# TMS320F280049 register map
Vendor: Texas Instruments; Series: C2000 F28004x; File version: 0.2.0-generated
Registers are 16-bit, read-write, reset 0x0 unless marked. A register's access mark holds for its fields unless they carry their own. Offsets are from the block's base; [hi:lo] are bit positions.

## ACCESSPROTECTIONREGS — ACCESS PROTECTION Registers
Base 0x000BE980
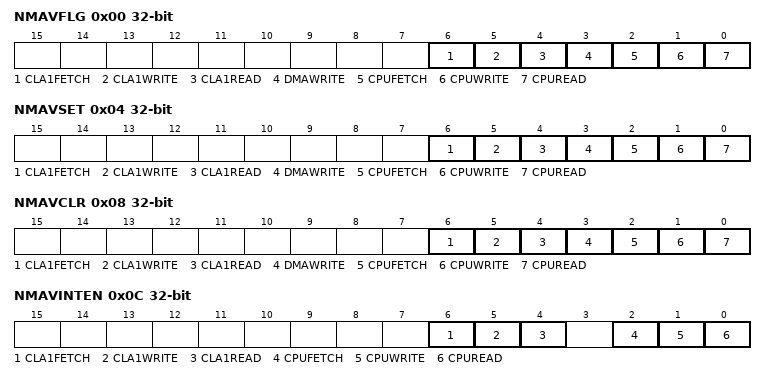
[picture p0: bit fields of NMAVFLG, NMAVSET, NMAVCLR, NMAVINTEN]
0x00 NMAVFLG 32-bit — Non-Master Access Violation Flag Register
  [6] CLA1FETCH — Non Master CLA1 Fetch Access Violation Flag
  [5] CLA1WRITE — Non Master CLA1 Write Access Violation Flag
  [4] CLA1READ — Non Master CLA1 Read Access Violation Flag
  [3] DMAWRITE — Non Master DMA Write Access Violation Flag
  [2] CPUFETCH — Non Master CPU Fetch Access Violation Flag
  [1] CPUWRITE — Non Master CPU Write Access Violation Flag
  [0] CPUREAD — Non Master CPU Read Access Violation Flag
0x04 NMAVSET 32-bit — Non-Master Access Violation Flag Set Register
  [6] CLA1FETCH — Non Master CLA1 Fetch Access Violation Flag Set
  [5] CLA1WRITE — Non Master CLA1 Write Access Violation Flag Set
  [4] CLA1READ — Non Master CLA1 Read Access Violation Flag Set
  [3] DMAWRITE — Non Master DMA Write Access Violation Flag Set
  [2] CPUFETCH — Non Master CPU Fetch Access Violation Flag Set
  [1] CPUWRITE — Non Master CPU Write Access Violation Flag Set
  [0] CPUREAD — Non Master CPU Read Access Violation Flag Set
0x08 NMAVCLR 32-bit — Non-Master Access Violation Flag Clear Register
  [6] CLA1FETCH — Non Master CLA1 Fetch Access Violation Flag Clear
  [5] CLA1WRITE — Non Master CLA1 Write Access Violation Flag Clear
  [4] CLA1READ — Non Master CLA1 Read Access Violation Flag Clear
  [3] DMAWRITE — Non Master DMA Write Access Violation Flag Clear
  [2] CPUFETCH — Non Master CPU Fetch Access Violation Flag Clear
  [1] CPUWRITE — Non Master CPU Write Access Violation Flag Clear
  [0] CPUREAD — Non Master CPU Read Access Violation Flag Clear
0x0C NMAVINTEN 32-bit — Non-Master Access Violation Interrupt Enable Register
  [6] CLA1FETCH — Non Master CLA1 Fetch Access Violation Interrupt Enable
  [5] CLA1WRITE — Non Master CLA1 Write Access Violation Interrupt Enable
  [4] CLA1READ — Non Master CLA1 Read Access Violation Interrupt Enable
  [2] CPUFETCH — Non Master CPU Fetch Access Violation Interrupt Enable
  [1] CPUWRITE — Non Master CPU Write Access Violation Interrupt Enable
  [0] CPUREAD — Non Master CPU Read Access Violation Interrupt Enable
0x10 NMCPURDAVADDR 32-bit — Non-Master CPU Read Access Violation Address
  [31] NMCPURDAVADDR — Non Master CPU read access violation address register.
0x14 NMCPUWRAVADDR 32-bit — Non-Master CPU Write Access Violation Address
  [31] NMCPUWRAVADDR — Non Master CPU write access violation address register.
0x18 NMCPUFAVADDR 32-bit — Non-Master CPU Fetch Access Violation Address
  [31] NMCPUFAVADDR — Non Master CPU fetch access violation address register.
0x1C NMDMAWRAVADDR 32-bit — Non-Master DMA Write Access Violation Address
0x20 NMCLA1RDAVADDR 32-bit — Non-Master CLA1 Read Access Violation Address
  [31] NMCLA1RDAVADDR — Non Master CLA1 read access violation address register.
0x24 NMCLA1WRAVADDR 32-bit — Non-Master CLA1 Write Access Violation Address
  [31] NMCLA1WRAVADDR — Non Master CLA1 write access violation address register.
0x28 NMCLA1FAVADDR 32-bit — Non-Master CLA1 Fetch Access Violation Address
  [31] NMCLA1FAVADDR — Non Master CLA1 fetch access violation address register.
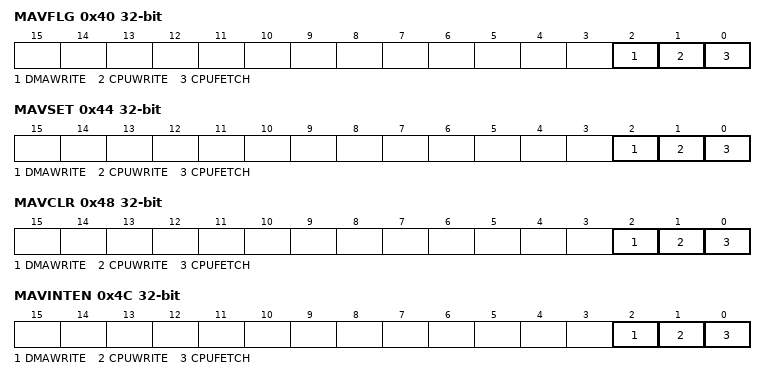
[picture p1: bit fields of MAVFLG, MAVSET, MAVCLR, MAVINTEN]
0x40 MAVFLG 32-bit — Master Access Violation Flag Register
  [2] DMAWRITE — Master DMA Write Access Violation Flag
  [1] CPUWRITE — Master CPU Write Access Violation Flag
  [0] CPUFETCH — Master CPU Fetch Access Violation Flag
0x44 MAVSET 32-bit — Master Access Violation Flag Set Register
  [2] DMAWRITE — Master DMA Write Access Violation Flag Set
  [1] CPUWRITE — Master CPU Write Access Violation Flag Set
  [0] CPUFETCH — Master CPU Fetch Access Violation Flag Set
0x48 MAVCLR 32-bit — Master Access Violation Flag Clear Register
  [2] DMAWRITE — Master DMA Write Access Violation Flag Clear
  [1] CPUWRITE — Master CPU Write Access Violation Flag Clear
  [0] CPUFETCH — Master CPU Fetch Access Violation Flag Clear
0x4C MAVINTEN 32-bit — Master Access Violation Interrupt Enable Register
  [2] DMAWRITE — Master DMA Write Access Violation Interrupt Enable
  [1] CPUWRITE — Master CPU Write Access Violation Interrupt Enable
  [0] CPUFETCH — Master CPU Fetch Access Violation Interrupt Enable
0x50 MCPUFAVADDR 32-bit — Master CPU Fetch Access Violation Address
  [31] MCPUFAVADDR — Master CPU fetch access violation address register.
0x54 MCPUWRAVADDR 32-bit — Master CPU Write Access Violation Address
  [31] MCPUWRAVADDR — Master CPU write access violation address register.
0x58 MDMAWRAVADDR 32-bit — Master DMA Write Access Violation Address
  [31] MDMAWRAVADDR — Master DMA write access violation address register.
